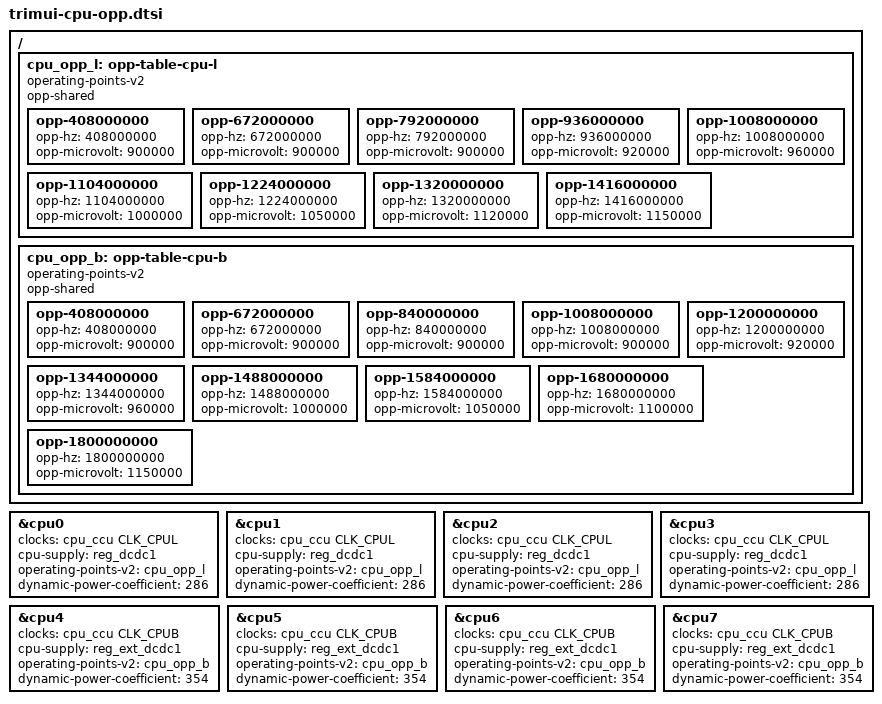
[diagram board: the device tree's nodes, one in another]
// SPDX-License-Identifier: (GPL-2.0-only OR MIT)
// Copyright (C) 2026 Midgy BALON
#include <dt-bindings/clock/sun55i-a523-cpu-ccu.h>	/* CLK_CPUL/CLK_CPUB, from patches 0015-0020 */
/*
 * STAGING — per-cluster CPU DVFS (cpufreq-dt) OPP tables. Both former blockers are
 * now resolved LOCALLY, so this fragment is fully wireable and builds. It stays in
 * staging because CPU DVFS is boot-critical and HW-UNVERIFIED — the CPU-CCU reprograms
 * the cluster PLLs and the OPP voltages are vendor-transcribed; enable + tune on the
 * device ([[hardware-testing-prevails]]). Include it from the board DTS to turn on
 * cpufreq. See docs/CPUPLL-NOTES.md, docs/ON-DEVICE-FINDINGS.md, dts/staging/README.md.
 *
 * UPSTREAM STATUS / why there is no separate "-upstream" rebase of this file
 * (unlike trimui-thermal-upstream.dtsi): the only SoC-level dependency here is the
 * A523 CPU-CCU, and — unlike the THS (Kalashnikov's near-merge series that redefines
 * the sensor nodes) — the CPU-CCU is *not* an external in-flight series. It is
 * ut-slayer's own UNMERGED work, adopted here verbatim as kernel/patches/0015-0020
 * (node `cpu_ccu` + macros CLK_CPUL/CLK_CPUB). There is nothing in v7.2 /
 * sunxi/for-next / linux-next (checked 2026-07-20). This file is therefore ALREADY
 * the board-only form — it defines no SoC infrastructure to shed. When the CPU-CCU
 * is properly upstreamed (Juan's to submit; per the linux-sunxi maintainer guidance),
 * the switch-over is simply: DROP kernel/patches/0015-0020 (the node + header then
 * come from mainline) and this file is used UNCHANGED — *provided* the upstream
 * binding keeps the same names. WATCH for a rename in review: if CLK_CPUL/CLK_CPUB,
 * the `allwinner,sun55i-a523-cpu-ccu` compatible, or the `cpu_ccu` label change
 * upstream (Andre already warned Juan's approach "might not be the right one"), the
 * `clocks = <&cpu_ccu CLK_CPU*>` references below must be updated to match.
 *
 * RESOLVED LOCALLY (both former blockers — via adoption, not yet upstream):
 *
 *  1. A523 CPU CLOCK — adopted from ut-slayer's CPU-CCU (kernel/patches/0015-0020,
 *     `&cpu_ccu` = clock-controller@8817000). The cpu nodes below use the real
 *     macros `&cpu_ccu CLK_CPUL` (cluster0) / `CLK_CPUB` (cluster1) from
 *     <dt-bindings/clock/sun55i-a523-cpu-ccu.h>.
 *
 *  2. BIG-CLUSTER REGULATOR — CONFIRMED ON HARDWARE 2026-07-22 to be **axp1530**
 *     @0x36 (dcdc1), NOT tcs4838 (0x41 is absent). axp1530 is already mainline
 *     (x-powers,axp1530), board node `&reg_ext_dcdc1`, so cluster1 does
 *     voltage-tracked DVFS. cluster0 uses reg_dcdc1 (axp717 dcdc1). (Patch 0014 /
 *     the tcs4838 driver + node were the wrong chip and are dropped.)
 *
 * FREQ/VOLTAGE POINTS — RESOLVED (was blocker #3). These are the REAL vendor
 * ladders, transcribed from the stock firmware `cluster0-opp-table` /
 * `cluster1-opp-table` (allwinner,sun50i-operating-points). The vendor board DTB
 * is BYTE-IDENTICAL between fw v1.0.1 and v1.0.2 (md5 967f1c68…), so these are
 * current. Vendor uses per-speed-bin voltage columns (opp-microvolt-vfXXYY keyed
 * off SID efuse); the single `opp-microvolt` below = the production bin (vf0100).
 * Sub-steps that only exist in some bins (cl0: 720/1032/1128/1296; cl1: 720/1248)
 * are OMITTED — keep the clean production ladder.
 *
 * Topology (from sun55i-a523.dtsi): two 4x Cortex-A55 clusters, separate rails:
 *   cluster0 = cpu0..cpu3 (cpu@0..@300)   -> cpu-supply = reg_dcdc1      (little)
 *   cluster1 = cpu4..cpu7 (cpu@400..@700) -> cpu-supply = axp1530 dcdc1  (big)
 *   (Confirmed on the stock OS: two cpufreq domains, policy0 = cpu0, policy4 = cpu4.)
 *
 * CEILINGS (vendor production bin vf0100):
 *   cluster0 little: 408 -> 1416 MHz  (0.90 -> 1.15 V)  -- fits reg_dcdc1 (0.90..1.16 V)
 *   cluster1 big:    408 -> 1800 MHz  (0.90 -> 1.15 V) nominal
 *   cluster1 turbo bins (better silicon only): 1992 @1.22V, 2088 @1.24V, 2160 @1.28V
 *     -- left COMMENTED; above the nominal ceiling, need axp1530 (raise its dcdc1 max) + THS + testing.
 *
 * RAIL LIMITS — voltages MUST stay inside the board-DTS regulator constraints:
 *   reg_dcdc1 "vdd-cpu": 900000..1160000 uV. The little-cluster ladder (max 1.15 V)
 *   fits. The big-cluster turbo rows would exceed a typical stock voltage and are
 *   gated on axp1530 dcdc1 headroom + THS thermal + on-device stability testing.
 */

/ {
	cpu_opp_l: opp-table-cpu-l {
		compatible = "operating-points-v2";
		opp-shared;	/* cpu0..3 change frequency together */

		opp-408000000 {
			opp-hz = /bits/ 64 <408000000>;
			opp-microvolt = <900000>;
		};
		opp-672000000 {
			opp-hz = /bits/ 64 <672000000>;
			opp-microvolt = <900000>;
		};
		opp-792000000 {
			opp-hz = /bits/ 64 <792000000>;
			opp-microvolt = <900000>;
		};
		opp-936000000 {
			opp-hz = /bits/ 64 <936000000>;
			opp-microvolt = <920000>;
		};
		opp-1008000000 {
			opp-hz = /bits/ 64 <1008000000>;
			opp-microvolt = <960000>;
		};
		opp-1104000000 {
			opp-hz = /bits/ 64 <1104000000>;
			opp-microvolt = <1000000>;
		};
		opp-1224000000 {
			opp-hz = /bits/ 64 <1224000000>;
			opp-microvolt = <1050000>;
		};
		opp-1320000000 {
			opp-hz = /bits/ 64 <1320000000>;
			opp-microvolt = <1120000>;
		};
		opp-1416000000 {
			opp-hz = /bits/ 64 <1416000000>;
			opp-microvolt = <1150000>;	/* little-cluster ceiling */
		};
	};

	cpu_opp_b: opp-table-cpu-b {
		compatible = "operating-points-v2";
		opp-shared;	/* cpu4..7 change frequency together */

		opp-408000000 {
			opp-hz = /bits/ 64 <408000000>;
			opp-microvolt = <900000>;
		};
		opp-672000000 {
			opp-hz = /bits/ 64 <672000000>;
			opp-microvolt = <900000>;
		};
		opp-840000000 {
			opp-hz = /bits/ 64 <840000000>;
			opp-microvolt = <900000>;
		};
		opp-1008000000 {
			opp-hz = /bits/ 64 <1008000000>;
			opp-microvolt = <900000>;
		};
		opp-1200000000 {
			opp-hz = /bits/ 64 <1200000000>;
			opp-microvolt = <920000>;
		};
		opp-1344000000 {
			opp-hz = /bits/ 64 <1344000000>;
			opp-microvolt = <960000>;
		};
		opp-1488000000 {
			opp-hz = /bits/ 64 <1488000000>;
			opp-microvolt = <1000000>;
		};
		opp-1584000000 {
			opp-hz = /bits/ 64 <1584000000>;
			opp-microvolt = <1050000>;
		};
		opp-1680000000 {
			opp-hz = /bits/ 64 <1680000000>;
			opp-microvolt = <1100000>;
		};
		opp-1800000000 {
			opp-hz = /bits/ 64 <1800000000>;
			opp-microvolt = <1150000>;	/* big-cluster nominal ceiling */
		};
		/* --- TURBO BINS: better-silicon only; need axp1530 (raise its dcdc1 max) + THS + testing ---
		opp-1992000000 {
			opp-hz = /bits/ 64 <1992000000>;
			opp-microvolt = <1220000>;
		};
		opp-2088000000 {
			opp-hz = /bits/ 64 <2088000000>;
			opp-microvolt = <1240000>;
		};
		opp-2160000000 {
			opp-hz = /bits/ 64 <2160000000>;
			opp-microvolt = <1280000>;
		};
		--- */
	};
};

/*
 * cluster0 (little) — cpu0..cpu3. Clock = &cpu_ccu CLK_CPUL; cpu-supply = reg_dcdc1.
 */
&cpu0 {
	clocks = <&cpu_ccu CLK_CPUL>;
	clock-names = "cpu";
	cpu-supply = <&reg_dcdc1>;
	operating-points-v2 = <&cpu_opp_l>;
	dynamic-power-coefficient = <286>;	/* VERIFY (vendor DTB); for EAS + IPA */
};

&cpu1 {
	clocks = <&cpu_ccu CLK_CPUL>;
	clock-names = "cpu";
	cpu-supply = <&reg_dcdc1>;
	operating-points-v2 = <&cpu_opp_l>;
	dynamic-power-coefficient = <286>;	/* VERIFY (vendor DTB); for EAS + IPA */
};

&cpu2 {
	clocks = <&cpu_ccu CLK_CPUL>;
	clock-names = "cpu";
	cpu-supply = <&reg_dcdc1>;
	operating-points-v2 = <&cpu_opp_l>;
	dynamic-power-coefficient = <286>;	/* VERIFY (vendor DTB); for EAS + IPA */
};

&cpu3 {
	clocks = <&cpu_ccu CLK_CPUL>;
	clock-names = "cpu";
	cpu-supply = <&reg_dcdc1>;
	operating-points-v2 = <&cpu_opp_l>;
	dynamic-power-coefficient = <286>;	/* VERIFY (vendor DTB); for EAS + IPA */
};

/*
 * cluster1 (big) — cpu4..cpu7. Clock = &cpu_ccu CLK_CPUB; cpu-supply =
 * reg_ext_dcdc1 = axp1530 dcdc1 (both resolved). Voltages are vendor-transcribed — tune on HW.
 */
&cpu4 {
	clocks = <&cpu_ccu CLK_CPUB>;
	clock-names = "cpu";
	cpu-supply = <&reg_ext_dcdc1>;	/* axp1530 dcdc1 (was tcs4838 — wrong chip, confirmed on HW) */
	operating-points-v2 = <&cpu_opp_b>;
	dynamic-power-coefficient = <354>;	/* VERIFY (vendor DTB); for EAS + IPA */
};

&cpu5 {
	clocks = <&cpu_ccu CLK_CPUB>;
	clock-names = "cpu";
	cpu-supply = <&reg_ext_dcdc1>;	/* axp1530 dcdc1 (was tcs4838 — wrong chip, confirmed on HW) */
	operating-points-v2 = <&cpu_opp_b>;
	dynamic-power-coefficient = <354>;	/* VERIFY (vendor DTB); for EAS + IPA */
};

&cpu6 {
	clocks = <&cpu_ccu CLK_CPUB>;
	clock-names = "cpu";
	cpu-supply = <&reg_ext_dcdc1>;	/* axp1530 dcdc1 (was tcs4838 — wrong chip, confirmed on HW) */
	operating-points-v2 = <&cpu_opp_b>;
	dynamic-power-coefficient = <354>;	/* VERIFY (vendor DTB); for EAS + IPA */
};

&cpu7 {
	clocks = <&cpu_ccu CLK_CPUB>;
	clock-names = "cpu";
	cpu-supply = <&reg_ext_dcdc1>;	/* axp1530 dcdc1 (was tcs4838 — wrong chip, confirmed on HW) */
	operating-points-v2 = <&cpu_opp_b>;
	dynamic-power-coefficient = <354>;	/* VERIFY (vendor DTB); for EAS + IPA */
};
